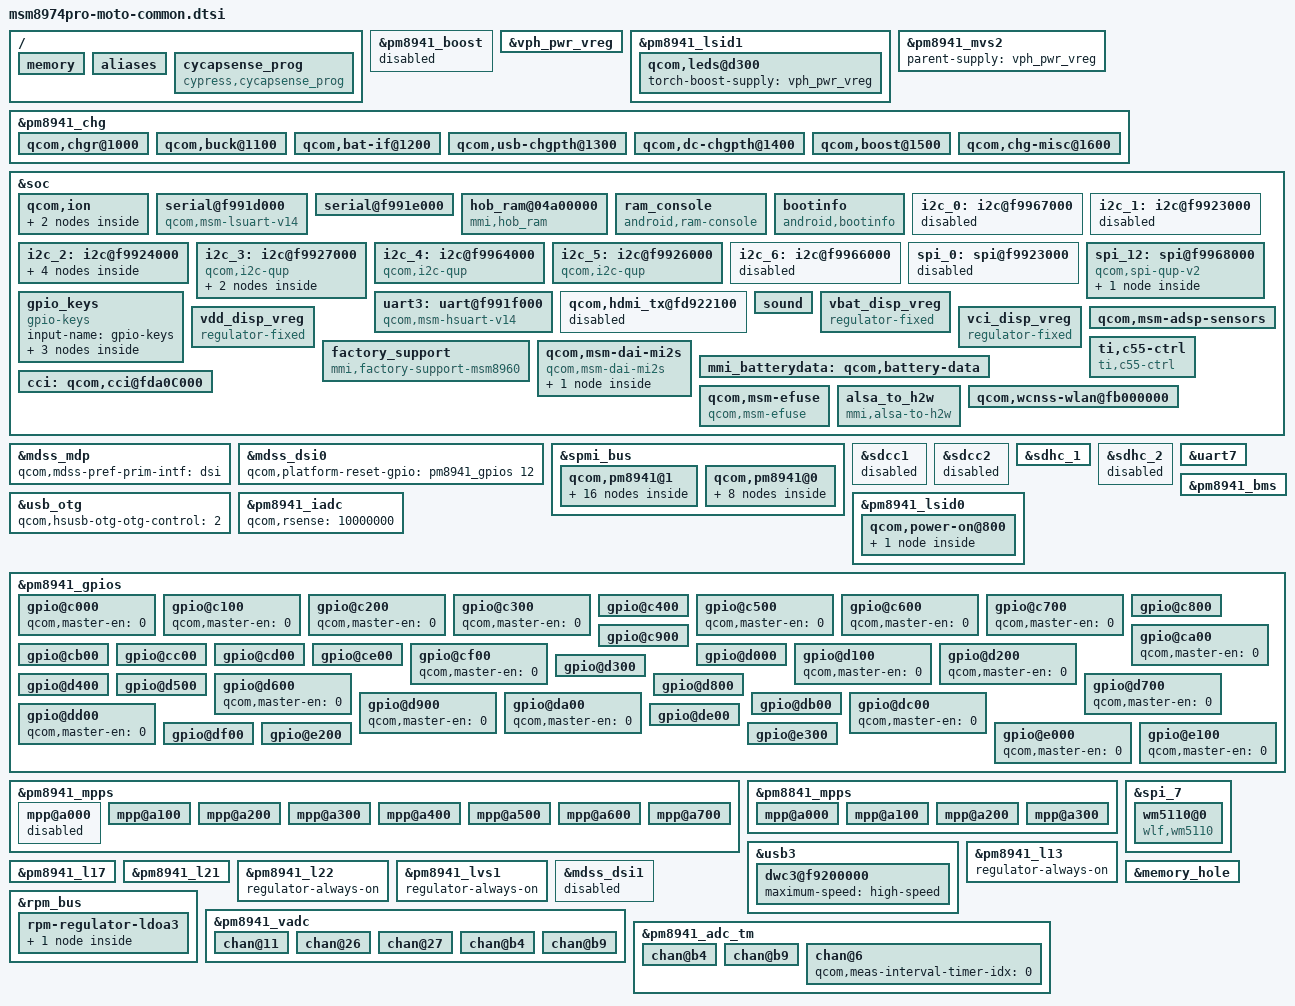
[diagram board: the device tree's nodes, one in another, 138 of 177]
/* Copyright (c) 2012-2013, The Linux Foundation. All rights reserved.
 * Copyright (c) 2013 Motorola Mobility LLC
 *
 * This program is free software; you can redistribute it and/or modify
 * it under the terms of the GNU General Public License version 2 and
 * only version 2 as published by the Free Software Foundation.
 *
 * This program is distributed in the hope that it will be useful,
 * but WITHOUT ANY WARRANTY; without even the implied warranty of
 * MERCHANTABILITY or FITNESS FOR A PARTICULAR PURPOSE.  See the
 * GNU General Public License for more details.
 */

/include/ "msm8974-leds.dtsi"
/include/ "msm8974-camera-sensor-moto.dtsi"
/include/ "dsi-panel-mot-dummy-qhd-video.dtsi"
/include/ "carrier-channel-ids.dtsi"

/ {
	memory {
		reg = <0x00000000 0x00000000>,
		      <0x00000000 0x00000000>;
	};

	aliases {
		uart3 = &uart3;
                spi12 = &spi_12;
	};

	cycapsense_prog {
			compatible = "cypress,cycapsense_prog";
			label = "cy8c20247_24lkxi";
			silicon_id = <0x0143>;
			block_size = <128>;
			num_of_blocks = <128>;
			secure_bytes = <16>;
			gpios = <&msmgpio 63 0>, /* RESET */
					<&msmgpio 111 0>, /* programming SCLK */
					<&msmgpio 110 0>; /* programming SDAT */
	};
};

&pm8941_boost {
	status = "disabled";
};

&vph_pwr_vreg {
	status = "ok";
};

&pm8941_lsid1 {
	qcom,leds@d300 {
		torch-boost-supply = <&vph_pwr_vreg>;
	};
};

&pm8941_mvs2 {
	parent-supply = <&vph_pwr_vreg>;
};

&pm8941_chg {
	otg-parent-supply = <&vph_pwr_vreg>;
};

&soc {
	qcom,ion {
		qcom,ion-heap@23 { /* OTHER PIL HEAP */
			qcom,memory-fixed = <0x05100000 0x2100000>;
		};

		qcom,ion-heap@26 { /* MODEM HEAP */
			qcom,memory-fixed = <0x07700000 0x5a00000>;
		};
	};

	serial@f991d000 {       /* "UART_AP_*_SP" on BLSP1 (BLSP1 UART0) */
		compatible = "qcom,msm-lsuart-v14";
		reg = <0xf991d000 0x1000>;
		interrupts = <0 107 0>;
		status = "ok";
	};

	serial@f991e000 {       /* "UART1DM" on BLSP2 (BLSP1 UART1) */
		status = "ok";
	};

	hob_ram@04a00000 {
		compatible = "mmi,hob_ram";
		reg = <0x04a00000 0x40000>,  /* hob address */
			  <0x04a40000 0x8000>; /* dhob address */
		qcom,memblock-reserve = <0x04a00000 0x48000>;
	};

	ram_console {
		compatible = "android,ram-console";
		status = "ok";

		android,ram-buffer-start = <0x3eae0000>;
		android,ram-buffer-size = <0x20000>;
	};

	bootinfo {
		compatible = "android,bootinfo";
		status = "ok";

		android,bootinfo-buffer-start = <0x3eb00000>;
		android,bootinfo-buffer-size = <0x800>;
	};


	i2c_0: i2c@f9967000 {   /* Unused on BLSP11 (BLSP2 QUP4) */
		status = "disabled";
		qcom,i2c-bus-freq = <400000>;
		qcom,i2c-src-freq = <50000000>;
	};

	i2c_1: i2c@f9923000 {   /* "I2C4" on BLSP1 (BLSP1 UART0) */
		status = "disabled";
		qcom,i2c-bus-freq = <400000>;
		qcom,i2c-src-freq = <50000000>;
	};

	i2c_2: i2c@f9924000 {   /* "I2C5" on BLSP2 (BLSP1 QUP1) */
		status = "ok";
	};

	i2c_3: i2c@f9927000 {   /* "I2C1" on BLSP5 (BLSP1 QUP4) */
		cell-index = <3>;
		compatible = "qcom,i2c-qup";
		reg = <0xf9927000 0x1000>;
		#address-cells = <1>;
		#size-cells = <0>;
		reg-names = "qup_phys_addr";
		interrupts = <0 99 0>;
		interrupt-names = "qup_err_intr";
		qcom,scl-gpio = <&msmgpio 26 0>;
		qcom,sda-gpio = <&msmgpio 25 0>;
		qcom,i2c-bus-freq = <400000>;
		qcom,i2c-src-freq = <50000000>;
		qcom,master-id = <86>;
	};

	i2c_4: i2c@f9964000 {   /* "I2C2" on BLSP8 (BLSP2 QUP1) */
		cell-index = <4>;
		compatible = "qcom,i2c-qup";
		reg = <0xf9964000 0x1000>;
		#address-cells = <1>;
		#size-cells = <0>;
		reg-names = "qup_phys_addr";
		interrupts = <0 102 0>;
		interrupt-names = "qup_err_intr";
		qcom,i2c-bus-freq = <100000>;
		qcom,i2c-src-freq = <50000000>;
		qcom,master-id = <84>;
	};

	i2c_5: i2c@f9926000 {   /* "I2C3" on BLSP4 (BLSP1 QUP3) */
		cell-index = <5>;
		compatible = "qcom,i2c-qup";
		reg = <0xf9926000 0x1000>;
		#address-cells = <1>;
		#size-cells = <0>;
		reg-names = "qup_phys_addr";
		interrupts = <0 98 0>;
		interrupt-names = "qup_err_intr";
		qcom,i2c-bus-freq = <100000>;
		qcom,i2c-src-freq = <50000000>;
		qcom,master-id = <86>;
	};

	i2c_6: i2c@f9966000 {   /* BLSP10 (BLSP2 QUP3) */
		status = "disabled";
	};

	spi_0: spi@f9923000 {
		status = "disabled";
	};

        /* BLSP12 (BLSP2 QUP5) VALIDITY CHANGE */
        spi_12: spi@f9968000 {
		compatible = "qcom,spi-qup-v2";
		cell-index = <12>;

		reg = <0xf9968000 0x1000>, <0xf9944000 0x19000>;
		reg-names = "spi_physical", "spi_bam_physical";

		interrupts = <0 106 0>, <0 239 0>;
		interrupt-names = "spi_irq", "spi_bam_irq";

		spi-max-frequency = <48000000>;
		#address-cells = <1>;
		#size-cells = <0>;
		gpios = <&msmgpio 88 0>,
			<&msmgpio 86 0>,
			<&msmgpio 85 0>;
		cs-gpios = <&msmgpio 87 0>;
		qcom,master-id = <84>;

		qcom,use-bam;
		qcom,bam-consumer-pipe-index = <22>;
		qcom,bam-producer-pipe-index = <23>;
		qcom,ver-reg-exists;

		validity-metallica@0{
			compatible = "validity,metallica";
			reg = <0>;
			spi-max-frequency = <17143000>;
		};
	};

	uart3: uart@f991f000 {  /* "UART_AP_*_C55" on BLSP3 (BLSP1 UART2) */
		compatible = "qcom,msm-hsuart-v14";
		reg = <0xf991f000 0x1000>,
			<0xf9904000 0x19000>;
		reg-names = "core_mem", "bam_mem";
		interrupt-parent = <&uart3>;
		#address-cells = <0>;
		interrupts = <0 1 2>;
		interrupt-names = "core_irq", "bam_irq", "wakeup_irq";
		#interrupt-cells = <1>;
		interrupt-map-mask = <0xffffffff>;
		interrupt-map = <0 &intc 0 109 0
				1 &intc 0 238 0
				2 &msmgpio 10 0>;
		qcom,bam-tx-ep-pipe-index = <4>;
		qcom,bam-rx-ep-pipe-index = <5>;
		qcom,msm-bus,name = "uart3";
		qcom,msm-bus,num-cases = <2>;
		qcom,msm-bus,num-paths = <1>;
		qcom,msm-bus,vectors-KBps =
				<86 512 0 0>,
				<86 512 500 800>;
	};

	qcom,hdmi_tx@fd922100 {
		status = "disabled";
	};

	gpio_keys {
		compatible = "gpio-keys";
		input-name = "gpio-keys";

		camera_snapshot {
			label = "camera_snapshot";
			gpios = <&pm8941_gpios 3 0x1>;
			linux,input-type = <1>;
			linux,code = <0x2fe>;
			gpio-key,wakeup;
			debounce-interval = <15>;
		};

		vol_down {
			label = "volume_down";
			gpios = <&pm8941_gpios 2 0x1>;
			linux,input-type = <1>;
			linux,code = <114>;
			gpio-key,wakeup;
			debounce-interval = <15>;
		};

		vol_up {
			label = "volume_up";
			gpios = <&pm8941_gpios 5 0x1>;
			linux,input-type = <1>;
			linux,code = <115>;
			gpio-key,wakeup;
			debounce-interval = <15>;
		};
	};

	sound {
		qcom,model = "msm8974-taiko-mtp-snd-card";
		qcom,cdc-micbias2-headset-only;
	};

	vbat_disp_vreg: vbat_disp_vreg {
		compatible = "regulator-fixed";
		regulator-name = "vbat_disp";
		gpio = <&pm8941_gpios 14 0x0>;
		parent-supply = <&vph_pwr_vreg>;
		startup-delay-us = <300>;
		enable-active-high;
	};

	vdd_disp_vreg: vdd_disp_vreg {
		compatible = "regulator-fixed";
		regulator-name = "vdd_disp";
		gpio = <&pm8941_gpios 23 0x0>;
		parent-supply = <&pm8941_s3>;
		startup-delay-us = <300>;
		enable-active-high;
	};

	vci_disp_vreg: vci_disp_vreg {
		compatible = "regulator-fixed";
		regulator-name = "vci_disp";
		gpio = <&pm8941_gpios 19 0>;
		parent-supply = <&pm8941_l23>;
		startup-delay-us = <300>;
		enable-active-high;
	};

	qcom,msm-adsp-sensors {
//		status = "disabled";
	};

	ti,c55-ctrl {
		compatible = "ti,c55-ctrl";
		reg = <0 0>;
		gpios = <&msmgpio 77 2>,        /* gpio_core */
			<&msmgpio 125 0>,       /* gpio_reset */
			<&msmgpio 79 1>,        /* gpio_ap_int */
			<&msmgpio 124 2>;       /* gpio_c55_int */
	};

	factory_support {
		compatible = "mmi,factory-support-msm8960";
		gpios = <&pm8941_gpios 36 0x2>; /* GPIOF_OUT_INIT_HIGH */
		gpio-names = "factory_kill_disable";
	};

	qcom,msm-dai-mi2s {
		compatible = "qcom,msm-dai-mi2s";
		qcom,msm-dai-q6-mi2s-prim {
			compatible = "qcom,msm-dai-q6-mi2s";
			qcom,msm-dai-q6-mi2s-dev-id = <0>;
			qcom,msm-mi2s-rx-lines = <2>;
			qcom,msm-mi2s-tx-lines = <1>;
		};
	};

	mmi_batterydata: qcom,battery-data {
		qcom,rpull-up-kohm = <100>;
		qcom,vref-batt-therm-uv = <1800000>;
		qcom,default-kohm = <130>;

		/include/ "batterydata-ey30-lg-fix.dtsi"
		/include/ "batterydata-ey30-lg.dtsi"
	};

	cci: qcom,cci@fda0C000 {
		gpios = <&msmgpio 21 0>,
			<&msmgpio 22 0>;
		qcom,gpio-tbl-num = <0 1>;
		qcom,gpio-tbl-flags = <1 1>;
		qcom,gpio-tbl-label = "CCI_I2C_DATA1",
			"CCI_I2C_CLK1";
		vddio-supply = <&pm8941_lvs3>;
	};
	qcom,msm-efuse {
		compatible = "qcom,msm-efuse";
		qcom,memory-reservation-type = "EBI1";
		qcom,memory-reservation-size = <0x1000>; /* 4kb from EBI1 buffer */
	};

	alsa_to_h2w {
		compatible = "mmi,alsa-to-h2w";
	};

	qcom,wcnss-wlan@fb000000 {
		qcom,iris-vddpa-supply = <&pm8941_l21>;
		qcom,cnss-pm = <11 21 1200 1 1>;
	};
};

&mdss_mdp {
	qcom,mdss-pref-prim-intf = "dsi";
};

&mdss_dsi0 {
	qcom,platform-reset-gpio = <&pm8941_gpios 12 0>;

	/* Remove unneeded DSI properties / supplies */
	/delete-property/ qcom,platform-enable-gpio;
	/delete-property/ qcom,platform-reset-sequence;

	/delete-node/ qcom,platform-supply-entry1;
};

&spmi_bus {
	qcom,pm8941@1 {

		qcom,leds@d000 {
			compatible = "qcom,leds-qpnp-rgb";
			qcom,rgb_0 {
				/delete-property/ qcom,default-state;
				/delete-property/ linux,default-trigger;
			};

			qcom,rgb_1 {
				/delete-property/ qcom,default-state;
				/delete-property/ linux,default-trigger;
			};

			qcom,rgb_2 {
				status = "ok";
			};

			qcom,rgb_3 {
				label = "combo";
				linux,name = "rgb";
				qcom,max-current = <12>;
				qcom,id = <9>;
			};

		};

		qcom,leds@d800 {
			status = "disabled";
		};

		qcom,leds@d900 {
			status = "disabled";
		};

		qcom,leds@da00 {
			status = "disabled";
		};

		qcom,leds@db00 {
			status = "disabled";
		};

		qcom,leds@dc00 {
			status = "disabled";
		};

		qcom,leds@dd00 {
			status = "disabled";
		};

		qcom,leds@de00 {
			status = "disabled";
		};

		qcom,leds@df00 {
			status = "disabled";
		};

		qcom,leds@e000 {
			status = "disabled";
		};

		qcom,leds@e100 {
			status = "disabled";
		};

		qcom,leds@e200 {
			status = "disabled";
		};
	};

	qcom,pm8941@0 {

		pm8941_chg_fac: qcom,chargerfac {
			spmi-dev-container;
			compatible = "qcom,qpnp-charger-factory";
			#address-cells = <1>;
			#size-cells = <1>;
			status = "ok";

			qcom,vddmax-mv = <4200>;
			qcom,vddsafe-mv = <4400>;
			qcom,vinmin-mv = <4300>;
			qcom,vbatdet-delta-mv = <150>;
			qcom,ibatmax-ma = <2000>;
			qcom,ibatterm-ma = <100>;
			qcom,ibatsafe-ma = <3250>;
			qcom,thermal-mitigation = <1500 700 600 325>;
			qcom,resume-soc = <99>;
			qcom,tchg-mins = <150>;
			qcom,chg-vadc = <&pm8941_vadc>;
			qcom,chg-adc_tm = <&pm8941_adc_tm>;
			qcom,ibatmax-warm-ma = <2600>;
			qcom,warm-bat-decidegc = <450>;
			qcom,warm-bat-mv = <4000>;
			qcom,cool-bat-decidegc = <10>;
			qcom,cool-bat-mv = <4000>;
			qcom,ibatmax-cool-ma = <2600>;
			qcom,batt-hot-percentage = <25>;
			qcom,batt-cold-percentage = <80>;
			qcom,ir-comp = <1>;

			qcom,chgr@1000 {
				status = "ok";
				reg = <0x1000 0x100>;
				interrupts =	<0x0 0x10 0x0>,
						<0x0 0x10 0x1>,
						<0x0 0x10 0x2>,
						<0x0 0x10 0x3>,
						<0x0 0x10 0x4>,
						<0x0 0x10 0x5>,
						<0x0 0x10 0x6>,
						<0x0 0x10 0x7>;

				interrupt-names =	"vbat-det-lo",
							"vbat-det-hi",
							"chgwdog",
							"state-change",
							"trkl-chg-on",
							"fast-chg-on",
							"chg-failed",
							"chg-done";
			};

			qcom,buck@1100 {
				status = "ok";
				reg = <0x1100 0x100>;
				interrupts =	<0x0 0x11 0x0>,
						<0x0 0x11 0x1>,
						<0x0 0x11 0x2>,
						<0x0 0x11 0x3>,
						<0x0 0x11 0x4>,
						<0x0 0x11 0x5>,
						<0x0 0x11 0x6>;

				interrupt-names =	"vbat-ov",
							"vreg-ov",
							"overtemp",
							"vchg-loop",
							"ichg-loop",
							"ibat-loop",
							"vdd-loop";
			};

			qcom,bat-if@1200 {
				status = "ok";
				reg = <0x1200 0x100>;
				interrupts =	<0x0 0x12 0x0>,
						<0x0 0x12 0x1>,
						<0x0 0x12 0x2>,
						<0x0 0x12 0x3>,
						<0x0 0x12 0x4>;

				interrupt-names =	"batt-pres",
							"bat-temp-ok",
							"bat-fet-on",
							"vcp-on",
							"psi";

			};

			qcom,usb-chgpth@1300 {
				status = "ok";
				reg = <0x1300 0x100>;
				interrupts =	<0 0x13 0x0>,
						<0 0x13 0x1>,
						<0x0 0x13 0x2>;

				interrupt-names =	"coarse-det-usb",
							"usbin-valid",
							"chg-gone";
			};

			qcom,dc-chgpth@1400 {
				status = "ok";
				reg = <0x1400 0x100>;
				interrupts =	<0x0 0x14 0x0>,
						<0x0 0x14 0x1>;

				interrupt-names =	"coarse-det-dc",
							"dcin-valid";
			};

			qcom,boost@1500 {
				status = "ok";
				reg = <0x1500 0x100>;
				interrupts =	<0x0 0x15 0x0>,
						<0x0 0x15 0x1>;

				interrupt-names =	"boost-pwr-ok",
							"limit-error";
			};

			qcom,misc@1600 {
				status = "ok";
				reg = <0x1600 0x100>;
			};
		};
	};
};

&sdcc1 {
	status = "disabled";
};

&sdcc2 {
	status = "disabled";
};

&sdhc_1 {
	vdd-supply = <&pm8941_l20>;
	vdd-io-supply = <&pm8941_s3>;

	qcom,vdd-always-on;
	qcom,vdd-lpm-sup;
	qcom,vdd-voltage-level = <2950000 2950000>;
	qcom,vdd-current-level = <800 500000>;

	qcom,vdd-io-always-on;
	qcom,vdd-io-voltage-level = <1800000 1800000>;
	qcom,vdd-io-current-level = <250 154000>;

	qcom,pad-pull-on = <0x0 0x3 0x3>; /* no-pull, pull-up, pull-up */
	qcom,pad-pull-off = <0x0 0x3 0x3>; /* no-pull, pull-up, pull-up */
	qcom,pad-drv-on = <0x4 0x4 0x4>; /* 10mA, 10mA, 10mA */
	qcom,pad-drv-off = <0x0 0x0 0x0>; /* 2mA, 2mA, 2mA */

	qcom,drv-types = <0x10>; /* 40 ohms */
	qcom,clk-rates = <400000 20000000 25000000 50000000 100000000 192000000 384000000>;
	qcom,bus-speed-mode = "HS200_1p8v", "DDR_1p8v";
	qcom,nonremovable;
	qcom,emmc;

	status = "ok";
};

&sdhc_2 {
	status = "disabled";
};

&usb_otg {
	qcom,hsusb-otg-otg-control = <2>;
};

&uart7 {
	status = "ok";
};

&pm8941_bms {
	qcom,r-sense-uohm = <10000>;
	qcom,v-cutoff-uv = <3000000>;
	qcom,max-voltage-uv = <4350000>;
	qcom,r-conn-mohm = <0>;
	qcom,shutdown-soc-valid-limit = <100>;
	qcom,adjust-soc-low-threshold = <15>;
	qcom,use-ocv-thresholds = <0>;
	qcom,low-soc-calculate-soc-threshold = <15>;
	qcom,low-soc-calculate-soc-ms = <5000>;
	qcom,calculate-soc-ms = <20000>;
	qcom,chg-term-ua = <100000>;
	qcom,batt-type = <0>;
	qcom,tm-temp-margin = <5000>;
	qcom,low-ocv-correction-limit-uv = <100>;
	qcom,high-ocv-correction-limit-uv = <50>;
	qcom,hold-soc-est = <3>;
	qcom,low-voltage-threshold = <3020000>;
	qcom,shutdown-voltage-uv = <2750000>;
	qcom,enable-fcc-learning = <1>;
	qcom,min-fcc-learning-soc = <20>;
	qcom,fcc-resolution = <10>;
	qcom,min-fcc-ocv-pc = <20>;
	qcom,min-fcc-learning-samples = <4>;
	qcom,use-external-rsense = <1>;
	qcom,battery-data = <&mmi_batterydata>;

	status = "ok";
};

&pm8941_chg {
	status = "ok";

	qcom,vddmax-mv = <4200>;
	qcom,vddsafe-mv = <4400>;
	qcom,vinmin-mv = <4300>;
	qcom,vbatdet-delta-mv = <150>;
	qcom,ibatmax-ma = <2600>;
	qcom,ibatterm-ma = <100>;
	qcom,ibatsafe-ma = <3250>;
	qcom,thermal-mitigation = <2600>, <2500>, <2400>, <2300>, <2200>,
				  <2100>, <2000>, <1900>, <1800>, <1700>,
				  <1600>, <1500>, <1400>, <1300>, <1200>,
				  <1100>, <1000>;
	qcom,tchg-mins = <512>;
	qcom,warm-bat-decidegc = <450>;
	qcom,cool-bat-decidegc = <0>;
	qcom,warm-bat-mv = <4000>;
	qcom,warm-bat-soc = <65>;
	qcom,resume-delta-soc = <2>;
	qcom,cool-bat-mv = <4000>;
	qcom,ibatmax-warm-ma = <2600>;
	qcom,ibatmax-cool-ma = <2600>;
	qcom,batt-hot-percentage = <25>;
	qcom,batt-cold-percentage = <80>;
	qcom,step-charge-voltage = <4200>;
	qcom,step-charge-soc = <50>;
	qcom,step-charge-current = <1500>;
	qcom,float-charge-timer = <1800>;
	qcom,ir-comp = <1>;
	qcom,battery-model-sysfs = <1>;

	qcom,chgr@1000 {
		status = "ok";
	};

	qcom,buck@1100 {
		status = "ok";
	};

	qcom,bat-if@1200 {
		status = "ok";
	};

	qcom,usb-chgpth@1300 {
		status = "ok";
	};

	qcom,dc-chgpth@1400 {
		status = "ok";
	};

	qcom,boost@1500 {
		status = "ok";
	};

	qcom,chg-misc@1600 {
		status = "ok";
	};
};

&pm8941_iadc {
	qcom,rsense = <10000000>;
};

&pm8941_lsid0  {
	qcom,power-on@800 {
		qcom,pon_2 {
			/delete-property/	qcom,support-reset;
			/delete-property/ 	qcom,s1-timer;
			/delete-property/ 	qcom,s2-timer;
			/delete-property/ 	qcom,s3-timer;
			/delete-property/ 	qcom,use-bark;
		};
	};
};

&pm8941_gpios {
	gpio@c000 { /* GPIO 1 */
		qcom,master-en = <0>;
	};

	gpio@c100 { /* GPIO 2 */
		qcom,master-en = <0>;
	};

	gpio@c200 { /* GPIO 3 */
		qcom,master-en = <0>;
	};

	gpio@c300 { /* GPIO 4 */
		qcom,master-en = <0>;
	};

	gpio@c400 { /* GPIO 5 */
		qcom,mode = <0>;        /* QPNP_PIN_MODE_DIG_IN */
		qcom,pull = <0>;        /* QPNP_PIN_PULL_UP_30  */
		qcom,vin-sel = <2>;     /* QPNP_PIN_VIN2  */
		qcom,src-sel = <0>;     /* QPNP_PIN_SEL_FUNC_CONSTANT */
		qcom,master-en = <1>;
	};

	gpio@c500 { /* GPIO 6 */
		qcom,master-en = <0>;
	};

	gpio@c600 { /* GPIO 7 */
		qcom,master-en = <0>;
	};

	gpio@c700 { /* GPIO 8 */
		qcom,master-en = <0>;
	};

	gpio@c800 { /* GPIO 9 */
		qcom,mode = <1>;          /* QPNP_PIN_MODE_DIG_OUT */
		qcom,out-strength = <1>;  /* QPNP_PIN_OUT_STRENGTH_LOW */
		qcom,src-sel = <2>;       /* QPNP_PIN_SEL_FUNC_1  */
		qcom,master-en = <1>;
	};

	gpio@c900 { /* GPIO 10 */
		qcom,master-en = <0>;
	};

	gpio@ca00 { /* GPIO 11 */
		qcom,master-en = <0>;
	};

	gpio@cb00 { /* GPIO 12 */
		qcom,mode = <1>;          /* QPNP_PIN_MODE_DIG_OUT */
		qcom,output-type = <0>;   /* QPNP_PIN_OUT_BUF_CMOS */
		qcom,pull = <5>;          /* QPNP_PIN_PULL_NO */
		qcom,vin-sel = <2>;       /* QPNP_PIN_VIN2 */
		qcom,out-strength = <1>;  /* QPNP_PIN_OUT_STRENGTH_LOW */
		qcom,src-sel = <0>;       /* QPNP_PIN_SEL_FUNC_CONSTANT */
		qcom,master-en = <1>;
	};

	gpio@cc00 { /* GPIO 13 */
		qcom,mode = <1>;          /* QPNP_PIN_MODE_DIG_OUT */
		qcom,out-strength = <1>;  /* QPNP_PIN_OUT_STRENGTH_LOW */
		qcom,src-sel = <1>;       /* QPNP_PIN_SEL_FUNC_1  */
		qcom,vin-sel = <2>;
		qcom,master-en = <1>;
	};

	gpio@cd00 { /* GPIO 14 */
		qcom,mode = <1>;          /* QPNP_PIN_MODE_DIG_OUT */
		qcom,output-type = <0>;   /* QPNP_PIN_OUT_BUF_CMOS */
		qcom,pull = <5>;          /* QPNP_PIN_PULL_NO */
		qcom,vin-sel = <2>;       /* QPNP_PIN_VIN2 */
		qcom,out-strength = <1>;  /* QPNP_PIN_OUT_STRENGTH_LOW */
		qcom,src-sel = <0>;       /* QPNP_PIN_SEL_FUNC_CONSTANT */
		qcom,master-en = <1>;
	};

	gpio@ce00 { /* GPIO 15 */
		qcom,mode = <1>;
		qcom,output-type = <0>;
		qcom,pull = <5>;
		qcom,vin-sel = <2>;
		qcom,out-strength = <1>;
		qcom,src-sel = <2>;
		qcom,master-en = <1>;
	};

	gpio@cf00 { /* GPIO 16 */
		qcom,master-en = <0>;
	};

	gpio@d000 { /* GPIO 17 */
	};

	gpio@d100 { /* GPIO 18 */
		qcom,master-en = <0>;
	};

	gpio@d200 { /* GPIO 19 */
		qcom,master-en = <0>;
	};

	gpio@d300 { /* GPIO 20 */
		qcom,mode = <1>;          /* QPNP_PIN_MODE_DIG_OUT */
		qcom,out-strength = <1>;  /* QPNP_PIN_OUT_STRENGTH_LOW */
		qcom,src-sel = <2>;       /* QPNP_PIN_SEL_FUNC_1  */
		qcom,master-en = <1>;
	};

	gpio@d400 { /* GPIO 21 */
	};

	gpio@d500 { /* GPIO 22 */
		qcom,mode = <0>;          /* QPNP_PIN_MODE_DIG_IN */
		qcom,pull = <1>;          /* 1.5 uA   */
		qcom,invert = <1>;        /* QPNP_PIN_INVERT_ENABLE */
		qcom,vin-sel = <2>;       /* QPNP_PIN_VIN2 */
		qcom,src-sel = <0>;       /* QPNP_PIN_SEL_FUNC_CONSTANT */
		qcom,master-en = <1>;
	};

	gpio@d600 { /* GPIO 23 */
		qcom,master-en = <0>;
	};

	gpio@d700 { /* GPIO 24 */
		qcom,master-en = <0>;
	};

	gpio@d800 { /* GPIO 25 */
		qcom,mode = <1>;          /* QPNP_PIN_MODE_DIG_OUT */
		qcom,out-strength = <1>;  /* QPNP_PIN_OUT_STRENGTH_LOW */
		qcom,src-sel = <1>;       /* QPNP_PIN_SEL_FUNC_1  */
		qcom,vin-sel = <2>;
		qcom,master-en = <1>;
	};

	gpio@d900 { /* GPIO 26 */
		qcom,master-en = <0>;
	};

	gpio@da00 { /* GPIO 27 */
		qcom,master-en = <0>;
	};

	gpio@db00 { /* GPIO 28 */
	};

	gpio@dc00 { /* GPIO 29 */
		qcom,master-en = <0>;
	};

	gpio@dd00 { /* GPIO 30 */
		qcom,master-en = <0>;
	};

	gpio@de00 { /* GPIO 31 */
	};

	gpio@df00 { /* GPIO 32 */
		qcom,mode = <0>;          /* QPNP_PIN_MODE_DIG_IN */
		qcom,pull = <4>;          /* QPNP_PIN_PULL_DN */
		qcom,src-sel = <2>;       /* QPNP_PIN_SEL_FUNC_1 */
		qcom,vin-sel = <2>;       /* QPNP_PIN_VIN2 */
		qcom,master-en = <1>;
	};

	gpio@e000 { /* GPIO 33 */
		qcom,master-en = <0>;
	};

	gpio@e100 { /* GPIO 34 */
		qcom,master-en = <0>;
	};

	gpio@e200 { /* GPIO 35 */
		qcom,mode = <0>;          /* QPNP_PIN_MODE_DIG_IN */
		qcom,pull = <4>;          /* QPNP_PIN_PULL_DN */
		qcom,master-en = <1>;
	};

	gpio@e300 { /* GPIO 36 */
		qcom,mode = <1>;          /* QPNP_PIN_MODE_DIG_OUT */
		qcom,vin-sel = <2>;       /* S3 */
		qcom,out-strength = <1>;  /* QPNP_PIN_OUT_STRENGTH_LOW */
		qcom,src-sel = <0>;       /* QPNP_PIN_SEL_FUNC_CONSTANT */
		qcom,master-en = <1>;
	};
};

&pm8941_mpps {

	mpp@a000 { /* MPP 1 */
		status = "disabled";
	};

	mpp@a100 { /* MPP 2 */
		qcom,mode = <0>;          /* QPNP_PIN_MODE_DIG_IN */
		qcom,vin-sel = <3>;       /* LDO6 1.8V */
		qcom,pull = <1>;          /* QPNP_PIN_MPP_PULL_UP_OPEN */
		qcom,ain-route = <1>;     /* QPNP_PIN_AIN_AMUX_CH6 */
		qcom,master-en = <1>;
	};

	mpp@a200 { /* MPP 3 */
	};

	mpp@a300 { /* MPP 4 */
	};

	mpp@a400 { /* MPP 5 */
		qcom,mode = <0>;          /* QPNP_PIN_MODE_DIG_IN */
		qcom,vin-sel = <2>;       /* PM8941_S3 1.8V */
		qcom,master-en = <1>;
	};

	mpp@a500 { /* MPP 6 */
		qcom,mode = <0>;          /* QPNP_PIN_MODE_DIG_IN */
		qcom,vin-sel = <2>;       /* PM8941_S3 1.8V */
		qcom,master-en = <1>;
	};

	mpp@a600 { /* MPP 7 */
		qcom,mode = <4>;          /* QPNP_PIN_MODE_AIN */
		qcom,ain-route = <2>;     /* QPNP_PIN_AIN_AMUX_CH7 */
		qcom,master-en = <1>;
	};

	mpp@a700 { /* MPP 8 */
		qcom,mode = <4>;          /* QPNP_PIN_MODE_AIN */
		qcom,ain-route = <3>;     /* QPNP_PIN_AIN_AMUX_CH8 */
		qcom,master-en = <1>;
	};
};

&pm8841_mpps {

	mpp@a000 { /* MPP 1 */
	};

	mpp@a100 { /* MPP 2 */
	};

	mpp@a200 { /* MPP 3 */
	};

	mpp@a300 { /* MPP 4 */
	};
};
/*
&slim_msm {
	taiko_codec {
		qcom,cdc-micbias1-ext-cap;
		qcom,cdc-micbias2-ext-cap;
		qcom,cdc-micbias4-ext-cap;
		qcom,cdc-reset-gpio = <&msmgpio 23 0>;
	};
};
*/

&spi_7 {
	wm5110@0 {
		compatible = "wlf,wm5110";
		spi-max-frequency = <9600000>;
		reg = <0x0>;
		interrupt-parent = <&msmgpio>;
		interrupts = <72 0>;
		irq-base = <800>;
		gpio-base = <200>;
		reset = <&msmgpio 23 0>;
		AVDD-supply = <&pm8941_s3>;
		DCVDD-supply = <&pm8941_s3>;
		DBVDD1-supply = <&pm8941_s3>;
		DBVDD2-supply = <&pm8941_s3>;
		DBVDD3-supply = <&pm8941_s3>;
		CPVDD-supply = <&pm8941_s3>;
		SPKVDDL-supply = <&vph_pwr_vreg>;
		SPKVDDR-supply = <&vph_pwr_vreg>;

		gpio-controller;
		#gpio-cells = <2>;

		gpio-defaults = <0x00002102
				0xffffffff
				0x00010000
				0x00000004
				0xffffffff>;
	};
};

&i2c_2 {
	tpa6165xx@40 {
		compatible = "ti,tpa6165";
		reg = <0x40>;
		interrupts = <&pm8941_gpios 22 0x1>;
		gpios = <&pm8941_gpios 22 0x1>;
		hs_det_vdd-supply = <&pm8941_lvs2>;
		hs_det_micvdd-supply = <&pm8941_l17>;
		ti,tpa6165-always-on-micbias = <1>;
		};

	tfa9890@34 {
		compatible = "nxp,tfa9890";
		reg = <0x34>;
		gpios = <&pm8941_gpios 20 0>;   /* RESET */
		tfa_vdd-supply = <&pm8941_s3>;
		nxp,tfa_max-vol-steps = <15>;
		};

	bcm2079x@76 {
		compatible = "brcm,bcm2079x";
		reg = <0x76>;
		interrupt-parent = <&msmgpio>;
		interrupts = <34 0x0>; /* NFC_IRQ */
		gpios = <&msmgpio 31 0x0>, /* NFC_WAKE */
			<&msmgpio 34 0x0>, /* NFC_IRQ */
			<&msmgpio 13 0x0>; /* REG_PU */
	};

	tmp108@48 {
		compatible = "ti,tmp108";
		reg = <0x48>;
		gpios = <&msmgpio 144 0>;
	};
};

&i2c_3 {
	/* TI drv2605 */
	drv2605@5a {
		compatible = "ti,drv2605";
		reg = <0x5A>;
		gpios = <&msmgpio 45 0>,        /* EN_GPIO */
			<&pm8941_mpps 2 0>;    /* Trigger */
		default_effect = <17>;          /* Strong Click 100% */
		external_trigger = <1>;
		rated_voltage = <0x72>;         /* 2.4v */
		overdrive_voltage = <0x89>;     /* 3.0v */
	};

	synaptics_dsx_i2c@20 {
		compatible = "synaptics,synaptics_dsx_i2c";
		reg = <0x20>;
		interrupt-parent = <&msmgpio>;
		interrupts = <62 0>;
		gpios = <&msmgpio 62 0>,        /* IRQ */
			<&msmgpio 57 0>;        /* RESET */
		touch_vdd-supply = <&pm8941_l23>;
		synaptics,normal-mode = <1>;
		synaptics,reset-on-resume;
		synaptics,hw-reset;
		synaptics,gpio-config;
	};
};

&usb3 {
	interrupt-parent = <&usb3>;
	interrupts = <0 1>;
	#interrupt-cells = <1>;
	interrupt-map-mask = <0x0 0xffffffff>;
	interrupt-map = <0x0 0 &intc 0 133 0
                         0x0 1 &spmi_bus 0x0 0x0 0xA1 0x0>;
	interrupt-names = "hs_phy_irq", "pmic_id_irq";
	qcom,otg-capability;
	pmic-id-gpio = <&pm8941_mpps 2 0>;    /* HOST_DET */
	pmic-id-amux-chan = <1>;              /* QPNP_PIN_AIN_AMUX_CH6 */
	pmic-id-pull = <1>;                   /* QPNP_PIN_MPP_PULL_UP_OPEN */
	pmic-id-vin = <3>;                    /* LDO6 1.8V */
	dwc3@f9200000 {
		maximum-speed = "high-speed";
	};
};

&pm8941_l13 {
	regulator-always-on;
};

&pm8941_l17 {
	regulator-always-on;
	qcom,init-ldo-mode = <1>;
};

&pm8941_l21 {
	regulator-min-microvolt = <2900000>;
	regulator-max-microvolt = <3350000>;
	qcom,init-voltage = <2900000>;
};

&pm8941_l22 {
	regulator-always-on;
};

&pm8941_lvs1 {
	regulator-always-on;
};

&pm8941_gpios {
	gpio@c900 { /* GPIO 10 */
		qcom,mode = <0>;          /* QPNP_PIN_MODE_DIG_IN */
	};
	gpio@d000 { /* GPIO 17 "SLEEP_CLK3" */
		qcom,mode = <1>;          /* OUT */
		qcom,vin-sel = <2>;       /* S3 */
		qcom,src-sel = <3>;       /* SLEEP_CLK3*/
	};
};

&spi_0 {
	status = "disabled";
};

&mdss_dsi1 {
	status = "disabled";
};

&memory_hole {
	qcom,memblock-remove = <0x05100000 0x8200000
				0x0fa00000 0x500000>; /* Address and size of the hole */
};

&rpm_bus {
	rpm-regulator-ldoa3 {
		status = "okay";
		pm8941_l3: regulator-l3 {
			regulator-min-microvolt = <1050000>;
			regulator-max-microvolt = <1225000>;
			qcom,init-voltage = <1050000>;
			status = "okay";
		};
	};
};

&pm8941_vadc {
	/delete-node/ chan@4;
	/delete-node/ chan@39;
	/delete-node/ chan@b3;
	/delete-node/ chan@b4;
	/delete-node/ chan@b7;
	/delete-node/ chan@b8;

	chan@11 {
		label = "host_det";
		reg = <0x11>;
		qcom,decimation = <0>;
		qcom,pre-div-channel-scaling = <1>;
		qcom,calibration-type = "absolute";
		qcom,scale-function = <0>;
		qcom,hw-settle-time = <0>;
		qcom,fast-avg-setup = <0>;
	};

	chan@26 {
		label = "bphi";
		reg = <0x26>;
		qcom,decimation = <0>;
		qcom,pre-div-channel-scaling = <1>;
		qcom,calibration-type = "absolute";
		qcom,scale-function = <0>;
		qcom,hw-settle-time = <0>;
		qcom,fast-avg-setup = <0>;
	};

	chan@27 {
		label = "rf_bphi";
		reg = <0x27>;
		qcom,decimation = <0>;
		qcom,pre-div-channel-scaling = <1>;
		qcom,calibration-type = "absolute";
		qcom,scale-function = <0>;
		qcom,hw-settle-time = <0>;
		qcom,fast-avg-setup = <0>;
	};

	chan@b4 {
		label = "pa_therm1";
		reg = <0xb4>;
		qcom,decimation = <0>;
		qcom,pre-div-channel-scaling = <0>;
		qcom,calibration-type = "ratiometric";
		qcom,scale-function = <2>;
		qcom,hw-settle-time = <2>;
		qcom,fast-avg-setup = <0>;
	};

	chan@b9 {
		label = "chg_therm";
		reg = <0xb9>;
		qcom,decimation = <0>;
		qcom,pre-div-channel-scaling = <0>;
		qcom,calibration-type = "ratiometric";
		qcom,scale-function = <2>;
		qcom,hw-settle-time = <2>;
		qcom,fast-avg-setup = <0>;
	};
};

&pm8941_adc_tm {
	/delete-node/ chan@b3;
	/delete-node/ chan@b4;
	/delete-node/ chan@b7;

	chan@b4 {
		label = "pa_therm1";
		reg = <0xb4>;
		qcom,decimation = <0>;
		qcom,pre-div-channel-scaling = <0>;
		qcom,calibration-type = "ratiometric";
		qcom,scale-function = <2>;
		qcom,hw-settle-time = <2>;
		qcom,fast-avg-setup = <3>;
		qcom,btm-channel-number = <0x88>;
		qcom,thermal-node;
	};

	chan@b9 {
		label = "chg_therm";
		reg = <0xb9>;
		qcom,decimation = <0>;
		qcom,pre-div-channel-scaling = <0>;
		qcom,calibration-type = "ratiometric";
		qcom,scale-function = <2>;
		qcom,hw-settle-time = <2>;
		qcom,fast-avg-setup = <3>;
		qcom,btm-channel-number = <0x48>;
		qcom,thermal-node;
	};
};

&pm8941_adc_tm {
	chan@6 {
		qcom,meas-interval-timer-idx = <0>;
	};
};
